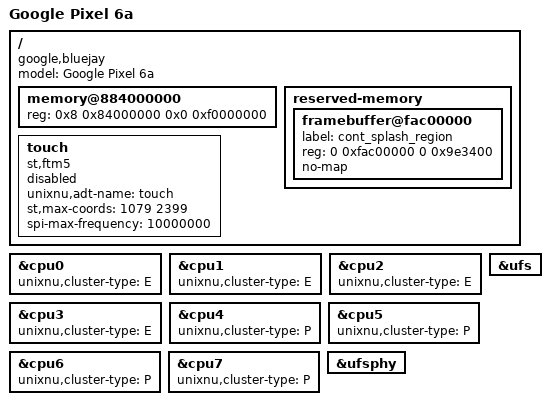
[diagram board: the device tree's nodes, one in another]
/dts-v1/;
/include/ "gs101.dtsi"

/ {
    model = "Google Pixel 6a";
    compatible = "google,bluejay", "google,gs101";

    // XNU receives the hole-free high DRAM range only. The low bank
    // (0x80000000, 2 GiB) is full of firmware no-map carve-outs, including
    // ABL's 16 MiB USB DMA region at 0xf8800000, so it is not described here.
    // The high pair is measured: 2 GiB at 0x880000000 and 2 GiB at
    // 0x900000000, contiguous, with no reservation inside. The first 64 MiB
    // (0x880000000..0x884000000) is the firmware's payload window: BootShim
    // copies the UniXNU payload there, so the free run starts at 0x884000000.
    // The run is NOT the full 0xfc000000: measured on the phone it is
    // 0xF89F6000, because the loader still holds the 49.5 MiB kernel image it
    // read from the payload while it places the window (it copies segments out
    // of that image afterwards), and that image lives at the top of DRAM.
    // DarwinBoot places the window at ALIGN(run, 2 MiB) + (kernel base &
    // 2 MiB - 1) = 0x884004000 for this kernel, then allocates exactly the
    // declared size there, so the declared size must leave that slack.
    // Declared here 0xf0000000 (3840 MiB): 137.9 MiB under the measured run,
    // which absorbs a varying kernel-image top. Declaring 0xfbe00000 failed
    // with Out of Resources (NO WINDOW FBE00000 BIG RUN F89F6000 @ 884000000).
    memory@884000000 {
        device_type = "memory";
        reg = <0x8 0x84000000 0x0 0xf0000000>;
    };

    reserved-memory {
        #address-cells = <2>;
        #size-cells = <2>;
        ranges;

        // Framebuffer set up by ABL: 1080x2400 a8r8g8b8, stride 4320.
        // It lives below the XNU range, so a no-map reservation is enough.
        framebuffer@fac00000 {
            label = "cont_splash_region";
            reg = <0 0xfac00000 0 0x9e3400>;
            no-map;
        };
    };

    touch {
        compatible = "st,ftm5";
        unixnu,adt-name = "touch";
        st,max-coords = <1079 2399>;
        spi-max-frequency = <10000000>;
        status = "disabled";        // driver pending (see porting.toml input area)
    };
};

// Tensor G1: 4x Cortex-A55 (E cluster) and 4x big cores (P cluster).
&cpu0 { unixnu,cluster-type = "E"; };
&cpu1 { unixnu,cluster-type = "E"; };
&cpu2 { unixnu,cluster-type = "E"; };
&cpu3 { unixnu,cluster-type = "E"; };
&cpu4 { unixnu,cluster-type = "P"; };
&cpu5 { unixnu,cluster-type = "P"; };
&cpu6 { unixnu,cluster-type = "P"; };
&cpu7 { unixnu,cluster-type = "P"; };

&ufs { status = "okay"; };
&ufsphy { status = "okay"; };
